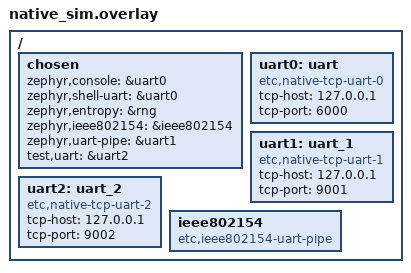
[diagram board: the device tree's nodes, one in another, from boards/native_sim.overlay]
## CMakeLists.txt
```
cmake_minimum_required(VERSION 3.13.1)
find_package(Zephyr REQUIRED HINTS $ENV{ZEPHYR_BASE})

project(app LANGUAGES C)

target_sources(app PRIVATE src/main.c)
```

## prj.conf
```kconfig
CONFIG_BT=n
CONFIG_GPIO=y
# Generic networking options
CONFIG_NETWORKING=y

# Network shell
CONFIG_SHELL=y
CONFIG_CONSOLE=y
CONFIG_NET_SHELL=y
CONFIG_SHELL_ARGC_MAX=26
CONFIG_SHELL_CMD_BUFF_SIZE=1024

#CONFIG_LOG=y
CONFIG_LOG_BUFFER_SIZE=32768

# Logging
# CONFIG_NET_LOG=y
# CONFIG_NET_CORE_LOG_LEVEL_DBG=y
# CONFIG_NET_IF_LOG_LEVEL_DBG=y
# CONFIG_NET_UTILS_LOG_LEVEL_DBG=y
# CONFIG_NET_PKT_LOG_LEVEL_DBG=y
# CONFIG_NET_ROUTE_LOG_LEVEL_DBG=y
# CONFIG_NET_CAPTURE_LOG_LEVEL_DBG=y
# CONFIG_NET_UDP_LOG_LEVEL_DBG=y
# CONFIG_IEEE802154_DRIVER_LOG_LEVEL_DBG=y
# CONFIG_OPENTHREAD_L2_DEBUG_DUMP_15_4=y
# CONFIG_OPENTHREAD_L2_DEBUG_DUMP_IPV6=y

CONFIG_REQUIRES_FULL_LIBC=y

# Disable TCP and IPv4 (TCP disabled to avoid heavy traffic)
CONFIG_NET_TCP=n
CONFIG_NET_IPV4=n

CONFIG_NET_IPV6_NBR_CACHE=n
CONFIG_NET_IPV6_MLD=n
CONFIG_NET_CONFIG_NEED_IPV4=n
CONFIG_NET_CONFIG_MY_IPV4_ADDR=""
CONFIG_NET_CONFIG_PEER_IPV4_ADDR=""

CONFIG_SYSTEM_WORKQUEUE_STACK_SIZE=2048
CONFIG_MAIN_STACK_SIZE=2560

CONFIG_IEEE802154=y


# Enable OpenThread shell
CONFIG_SHELL=y
CONFIG_NET_SHELL=y

CONFIG_SHELL_STACK_SIZE=3072



# logging
#CONFIG_LOG=y
#CONFIG_APP_LOG_LEVEL_DBG=y
CONFIG_DEBUG_OPTIMIZATIONS=y

#CONFIG_NET_CONFIG_MY_IPV6_ADDR="fdde:ad00:beef::2"
#CONFIG_NET_CONFIG_PEER_IPV6_ADDR="fdde:ad00:beef::1"

# mbedTLS tweaks
CONFIG_MBEDTLS_SSL_MAX_CONTENT_LEN=768

# Enable diagnostic module, uncomment if needed

CONFIG_NET_STATISTICS=y



#CONFIG_NET_L2_DUMMY=y
#CONFIG_NET_L2_ETHERNET=y

CONFIG_OPENTHREAD_MANUAL_START=n
CONFIG_OPENTHREAD_CHANNEL=26
CONFIG_OPENTHREAD_NETWORK_NAME="ot_sim"
CONFIG_OPENTHREAD_PANID=10000
CONFIG_OPENTHREAD_XPANID="fb:02:00:00:ab:cd:00:00"
CONFIG_OPENTHREAD_NETWORKKEY="00:11:22:33:44:55:66:77:88:99:aa:bb:cc:dd:ee:ff"
#CONFIG_OPENTHREAD_JOINER=y
#CONFIG_OPENTHREAD_JOINER_AUTOSTART=y
#CONFIG_OPENTHREAD_JOINER_PSKD="J01NU5"
#CONFIG_OPENTHREAD_SLAAC=y



CONFIG_OPENTHREAD_THREAD_VERSION_1_3_1=y
CONFIG_NET_L2_OPENTHREAD=y
CONFIG_OPENTHREAD_SHELL=y
CONFIG_OPENTHREAD_DEBUG=y
CONFIG_OPENTHREAD_L2_DEBUG=y
CONFIG_OPENTHREAD_L2_LOG_LEVEL_DBG=y

CONFIG_OPENTHREAD_FTD=y
CONFIG_OPENTHREAD_COAP=y
CONFIG_OPENTHREAD_COAPS=y
CONFIG_OPENTHREAD_COMMISSIONER=y
CONFIG_OPENTHREAD_DIAG=y
CONFIG_OPENTHREAD_DNS_CLIENT=y
CONFIG_OPENTHREAD_DHCP6_SERVER=y
CONFIG_OPENTHREAD_DHCP6_CLIENT=y
CONFIG_OPENTHREAD_ECDSA=y
CONFIG_OPENTHREAD_ENABLE_SERVICE=y
CONFIG_OPENTHREAD_EXTERNAL_HEAP=y
CONFIG_OPENTHREAD_IP6_FRAGM=y
CONFIG_OPENTHREAD_JAM_DETECTION=y
CONFIG_OPENTHREAD_JOINER=y
CONFIG_OPENTHREAD_MAC_FILTER=y
CONFIG_OPENTHREAD_NETDIAG_CLIENT=y
CONFIG_OPENTHREAD_RAW=y
CONFIG_OPENTHREAD_SLAAC=y
CONFIG_OPENTHREAD_SNTP_CLIENT=y
CONFIG_OPENTHREAD_SRP_CLIENT=y
CONFIG_OPENTHREAD_UDP_FORWARD=y
CONFIG_OPENTHREAD_DATASET_UPDATER=y
```

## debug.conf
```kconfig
# Copyright (c) 2021 Nordic Semiconductor ASA
# SPDX-License-Identifier: Apache-2.0
#
# This is a Kconfig fragment which can be used to enable debug-related options
# in the application. See the README for more details.

# compiler
#CONFIG_DEBUG_OPTIMIZATIONS=y

# logging
#CONFIG_LOG=y
#CONFIG_APP_LOG_LEVEL_DBG=y
```

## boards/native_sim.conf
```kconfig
CONFIG_BT=n


# compiler
CONFIG_DEBUG_OPTIMIZATIONS=y
CONFIG_IDLE_STACK_SIZE=2048  
CONFIG_NO_OPTIMIZATIONS=y 
#CONFIG_DEBUG=y
CONFIG_CONSOLE=y

CONFIG_REQUIRES_FULL_LIBC=y
CONFIG_MULTITHREADING=n

CONFIG_PRINTK=y
CONFIG_SERIAL=y
CONFIG_UART_USE_RUNTIME_CONFIGURE=y
CONFIG_UART_INTERRUPT_DRIVEN=y

CONFIG_NET_SLIP_TAP=n


#CONFIG_ARCH_POSIX_RECOMMENDED_STACK_SIZE=2048
CONFIG_IEEE802154_ETC_UPIPE_HW_FILTER=n
CONFIG_NET_PKT_TIMESTAMP=y
#CONFIG_NET_PKT_TXTIME=n

#CONFIG_UART_NATIVE_POSIX=y
#CONFIG_UART_NATIVE_TTY=y
#CONFIG_UART_NATIVE_POSIX_PORT_1_ENABLE=y
```

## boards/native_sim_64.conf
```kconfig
CONFIG_BT=n


# compiler
CONFIG_DEBUG_OPTIMIZATIONS=y
CONFIG_IDLE_STACK_SIZE=2048  
CONFIG_NO_OPTIMIZATIONS=y 
#CONFIG_DEBUG=y
CONFIG_CONSOLE=y

CONFIG_REQUIRES_FULL_LIBC=y
CONFIG_MULTITHREADING=n

CONFIG_PRINTK=y
CONFIG_SERIAL=y
CONFIG_UART_USE_RUNTIME_CONFIGURE=y
CONFIG_UART_INTERRUPT_DRIVEN=y

CONFIG_NET_SLIP_TAP=n


#CONFIG_ARCH_POSIX_RECOMMENDED_STACK_SIZE=2048

CONFIG_NET_PKT_TIMESTAMP=y
#CONFIG_NET_PKT_TXTIME=n

#CONFIG_UART_NATIVE_POSIX=y
#CONFIG_UART_NATIVE_TTY=y
#CONFIG_UART_NATIVE_POSIX_PORT_1_ENABLE=y
```

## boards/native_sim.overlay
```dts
/ {
	chosen {
        zephyr,console = &uart0;
		zephyr,shell-uart = &uart0;
        zephyr,entropy = &rng;
		zephyr,ieee802154 = &ieee802154;
		zephyr,uart-pipe = &uart1;
		test,uart = &uart2;
    };

	uart0: uart {
		status = "okay";
		compatible = "etc,native-tcp-uart-0";
		tcp-host = "127.0.0.1";
		tcp-port = <6000>;
	};

	uart1: uart_1 {
		status = "okay";
		compatible = "etc,native-tcp-uart-1";
		tcp-host = "127.0.0.1";
		tcp-port = <9001>;
	};

	uart2: uart_2 {
		status = "okay";
		compatible = "etc,native-tcp-uart-2";
		tcp-host = "127.0.0.1";
		tcp-port = <9002>;
	};

    ieee802154: ieee802154 {
	 	status = "okay";
		//status = "disabled";
	 	compatible = "etc,ieee802154-uart-pipe";
	 	//compatible = "nordic,nrf5x-ieee802154";
	};

};
```

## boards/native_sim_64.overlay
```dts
/ {
	chosen {
        zephyr,console = &uart2;
		zephyr,shell-uart = &uart0;
        zephyr,entropy = &rng;
		zephyr,ieee802154 = &ieee802154;
		zephyr,uart-pipe = &uart1;
		test,uart = &uart2;
    };

	uart0: uart {
		status = "okay";
		compatible = "etc,native-tcp-uart-0";
		tcp-host = "127.0.0.1";
		tcp-port = <6000>;
	};

	uart1: uart_1 {
		status = "okay";
		compatible = "etc,native-tcp-uart-1";
		tcp-host = "127.0.0.1";
		tcp-port = <9001>;
	};

	uart2: uart_2 {
		status = "okay";
		compatible = "etc,native-tcp-uart-2";
		tcp-host = "127.0.0.1";
		tcp-port = <9002>;
	};

    ieee802154: ieee802154 {
	 	status = "okay";
		//status = "disabled";
	 	compatible = "etc,ieee802154-uart-pipe";
	 	//compatible = "nordic,nrf5x-ieee802154";
	};

};
```

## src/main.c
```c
/*
 * Copyright (c) 2021 Nordic Semiconductor ASA
 * SPDX-License-Identifier: Apache-2.0
 */
#include <stdio.h>
#include <zephyr/kernel.h>
#include <zephyr/drivers/gpio.h>
#include <zephyr/logging/log.h>
#include <zephyr/drivers/uart.h>

#include <string.h>

#define SLEEP_TIME_MS   1000
#if 0
/* change this to any other UART peripheral if desired */
#define UART_DEVICE_NODE DT_CHOSEN(test_uart)

#define MSG_SIZE 32

/* queue to store up to 10 messages (aligned to 4-byte boundary) */
K_MSGQ_DEFINE(uart_msgq, MSG_SIZE, 10, 4);

static const struct device *const uart_dev = NULL; //DEVICE_DT_GET(UART_DEVICE_NODE);

/* receive buffer used in UART ISR callback */
static char rx_buf[MSG_SIZE];
static int rx_buf_pos;

/*
 * Read characters from UART until line end is detected. Afterwards push the
 * data to the message queue.
 */
void serial_cb(const struct device *dev, void *user_data)
{
	uint8_t c;

	if (!uart_irq_update(uart_dev)) {
		return;
	}

	if (!uart_irq_rx_ready(uart_dev)) {
		return;
	}

	/* read until FIFO empty */
	while (uart_fifo_read(uart_dev, &c, 1) == 1) {
		if ((c == '\n' || c == '\r') && rx_buf_pos > 0) {
			/* terminate string */
			rx_buf[rx_buf_pos] = '\0';

			/* if queue is full, message is silently dropped */
			k_msgq_put(&uart_msgq, &rx_buf, K_NO_WAIT);

			/* reset the buffer (it was copied to the msgq) */
			rx_buf_pos = 0;
		} else if (rx_buf_pos < (sizeof(rx_buf) - 1)) {
			rx_buf[rx_buf_pos++] = c;
		}
		/* else: characters beyond buffer size are dropped */
	}
}

/*
 * Print a null-terminated string character by character to the UART interface
 */
void print_uart(char *buf)
{
	int msg_len = strlen(buf);

	for (int i = 0; i < msg_len; i++) {
		uart_poll_out(uart_dev, buf[i]);
	}
}

int main(void)
{
	char tx_buf[MSG_SIZE];

	if (!device_is_ready(uart_dev)) {
		printk("UART device not found!");
		return 0;
	}

	/* configure interrupt and callback to receive data */
	int ret = uart_irq_callback_user_data_set(uart_dev, serial_cb, NULL);

	if (ret < 0) {
		if (ret == -ENOTSUP) {
			printk("Interrupt-driven UART API support not enabled\n");
		} else if (ret == -ENOSYS) {
			printk("UART device does not support interrupt-driven API\n");
		} else {
			printk("Error setting UART callback: %d\n", ret);
		}
		return 0;
	}
	uart_irq_rx_enable(uart_dev);

	print_uart("Hello! I'm your echo bot.\r\n");
	print_uart("Tell me something and press enter:\r\n");

	/* indefinitely wait for input from the user */
	while (k_msgq_get(&uart_msgq, &tx_buf, K_FOREVER) == 0) {
		print_uart("Echo: ");
		print_uart(tx_buf);
		print_uart("\r\n");
	}
	return 0;
}

#else

int main(void)
{
	while (1)
	{
		k_sleep(K_MSEC(1000));
	}
	return 0;
}

#endif
```
